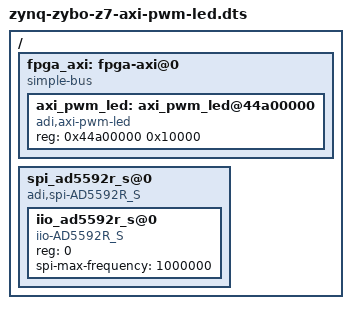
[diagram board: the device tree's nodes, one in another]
// SPDX-License-Identifier: GPL-2.0+
/dts-v1/;
#include "zynq-zybo-z7.dts"

/ {
	fpga_axi: fpga-axi@0 {
		compatible = "simple-bus";
		#address-cells = <0x1>;
		#size-cells = <0x1>;
		ranges;

		axi_pwm_led: axi_pwm_led@44a00000 {
			compatible = "adi,axi-pwm-led";
			reg = <0x44a00000 0x10000>;
		};
	};

	spi_ad5592r_s@0 {
		compatible = "adi,spi-AD5592R_S";
		#address-cells = <1>;
		#size-cells = <0>;

		iio_ad5592r_s@0 {
			compatible = "iio-AD5592R_S";
			reg = <0>;
			spi-max-frequency = <1000000>;
		};
	};
};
